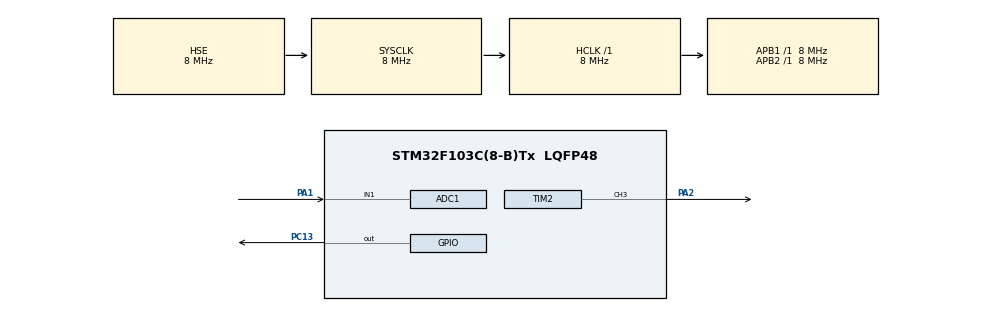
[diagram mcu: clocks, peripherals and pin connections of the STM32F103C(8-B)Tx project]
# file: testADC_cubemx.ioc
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ADC1.Channel-0\#ChannelRegularConversion=ADC_CHANNEL_1
ADC1.ContinuousConvMode=DISABLE
ADC1.ExternalTrigConv=ADC_EXTERNALTRIGCONV_T4_CC4
ADC1.NbrOfConversionFlag=1
ADC1.Rank-0\#ChannelRegularConversion=1
ADC1.SamplingTime-0\#ChannelRegularConversion=ADC_SAMPLETIME_1CYCLE_5
ADC1.master=1
Dma.ADC1.0.Direction=DMA_PERIPH_TO_MEMORY
Dma.ADC1.0.Instance=DMA1_Channel1
Dma.ADC1.0.MemDataAlignment=DMA_MDATAALIGN_HALFWORD
Dma.ADC1.0.MemInc=DMA_MINC_ENABLE
Dma.ADC1.0.Mode=DMA_CIRCULAR
Dma.ADC1.0.PeriphDataAlignment=DMA_PDATAALIGN_HALFWORD
Dma.ADC1.0.PeriphInc=DMA_PINC_DISABLE
Dma.ADC1.0.Priority=DMA_PRIORITY_HIGH
Dma.Request0=ADC1
Mcu.Family=STM32F1
Mcu.Name=STM32F103C(8-B)Tx
Mcu.Package=LQFP48
NVIC.DMA1_Channel1_IRQn=true\:0\:0\:false\:false\:true\:false\:true\:true
NVIC.PriorityGroup=NVIC_PRIORITYGROUP_4
NVIC.TIM4_IRQn=true\:0\:0\:false\:false\:true\:true\:true\:true
PA1.Signal=ADCx_IN1
PA13.Mode=Serial_Wire
PA13.Signal=SYS_JTMS-SWDIO
PA14.Mode=Serial_Wire
PA14.Signal=SYS_JTCK-SWCLK
PA2.Signal=S_TIM2_CH3
PC13-TAMPER-RTC.Signal=GPIO_Output
PD0-OSC_IN.Mode=HSE-External-Oscillator
PD0-OSC_IN.Signal=RCC_OSC_IN
PD1-OSC_OUT.Mode=HSE-External-Oscillator
PD1-OSC_OUT.Signal=RCC_OSC_OUT
ProjectManager.HeapSize=0x200
ProjectManager.StackSize=0x400
ProjectManager.TargetToolchain=MDK-ARM V5.32
RCC.ADCPresc=RCC_ADCPCLK2_DIV6
RCC.AHBFreq_Value=8000000
RCC.APB1Freq_Value=8000000
RCC.APB1TimFreq_Value=8000000
RCC.APB2Freq_Value=8000000
RCC.APB2TimFreq_Value=8000000
RCC.HCLKFreq_Value=8000000
RCC.SYSCLKFreq_VALUE=8000000
RCC.SYSCLKSource=RCC_SYSCLKSOURCE_HSE
RCC.USBFreq_Value=8000000
SH.ADCx_IN1.0=ADC1_IN1,IN1
SH.S_TIM2_CH3.0=TIM2_CH3,PWM Generation3 CH3
TIM2.Channel-PWM\ Generation3\ CH3=TIM_CHANNEL_3
TIM2.Period=4090
TIM2.Prescaler=8
TIM4.Channel-Output\ Compare4\ No\ Output=TIM_CHANNEL_4
TIM4.OCMode_4=TIM_OCMODE_TOGGLE
TIM4.Period=100
TIM4.Prescaler=3
TIM4.TIM_MasterOutputTrigger=TIM_TRGO_UPDATE
VP_TIM2_VS_ClockSourceINT.Mode=Internal
VP_TIM4_VS_ClockSourceINT.Mode=Internal
VP_TIM4_VS_no_output4.Mode=Output Compare4 No Output
board=custom

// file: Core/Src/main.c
/* USER CODE BEGIN Header */
/**
  ******************************************************************************
  * @file           : main.c
  * @brief          : Main program body
  ******************************************************************************
  * @attention
  *
  * Copyright (c) 2023 STMicroelectronics.
  * All rights reserved.
  *
  * This software is licensed under terms that can be found in the LICENSE file
  * in the root directory of this software component.
  * If no LICENSE file comes with this software, it is provided AS-IS.
  *
  ******************************************************************************
  */

/* USER CODE END Header */
#include "main.h"

//! Таймер для ШИМ
TIM_HandleTypeDef htim2;
//! Таймер для запуска АЦП
TIM_HandleTypeDef htim4;

/* USER CODE BEGIN PV */
//! массив сырых данных с АЦП
uint16_t 	adcData[ADC_SAMPLES];
//! среднее значение сырых данных
uint32_t 	adcAVG;
//! напряжение в мВ
uint32_t	adcVoltage;

//! флаг 25мс
uint8_t 	flg25ms;
//! сумма напряжений в мв за 1 сек
uint32_t 	adcSum1sec;
//! счетчик кол-ва 25мс
uint8_t 	cnt25ms;

/* USER CODE END PV */

void SystemClock_Config(void);
static void MX_GPIO_Init(void);
static void MX_DMA_Init(void);
static void MX_ADC1_Init(void);
static void MX_TIM2_Init(void);
static void MX_TIM4_Init(void);

/* USER CODE BEGIN 0 */

#include <stdio.h>

#define ITM_Port8(n)    (*((volatile unsigned char *)(0xE0000000+4*n)))
#define ITM_Port16(n)   (*((volatile unsigned short*)(0xE0000000+4*n)))
#define ITM_Port32(n)   (*((volatile unsigned long *)(0xE0000000+4*n)))
#define DEMCR           (*((volatile unsigned long *)(0xE000EDFC)))
#define TRCENA          0x01000000

struct __FILE { int handle; /* Add whatever you need here */ };

FILE __stdout;
FILE __stdin;

int fputc(int ch, FILE *f)
{
		if (DEMCR & TRCENA)
		{

			while (ITM_Port32(0) == 0);
			ITM_Port8(0) = ch;
		}
		return(ch);
}
/*
int _write(int32_t file, uint8_t *ptr, int32_t len)
{
    for (int i = 0; i < len; i++)
    {
        ITM_SendChar(*ptr++);
    }
    return len;
}
*/
/* USER CODE END 0 */

int main(void)
{

  /* MCU Configuration--------------------------------------------------------*/

  /* Reset of all peripherals, Initializes the Flash interface and the Systick. */
  HAL_Init();

  /* Configure the system clock */
  SystemClock_Config();

  /* Initialize all configured peripherals */
  MX_GPIO_Init();
  MX_DMA_Init();
  MX_ADC1_Init();
  MX_TIM2_Init();
  MX_TIM4_Init();
  /* USER CODE BEGIN 2 */

#ifdef ADC_LL
	//LL_ADC_REG_StartConversionSWStart(ADC1);
	LL_DMA_SetDataLength(DMA1, LL_DMA_CHANNEL_1, ADC_SAMPLES);

	LL_DMA_ConfigTransfer(DMA1,
                        LL_DMA_CHANNEL_1,
                        LL_DMA_DIRECTION_PERIPH_TO_MEMORY |
                        LL_DMA_MODE_CIRCULAR              |
                        LL_DMA_PERIPH_NOINCREMENT         |
                        LL_DMA_MEMORY_INCREMENT           |
                        LL_DMA_PDATAALIGN_HALFWORD        |
                        LL_DMA_MDATAALIGN_HALFWORD        |
                        LL_DMA_PRIORITY_HIGH               );

  LL_DMA_ConfigAddresses(DMA1,
                         LL_DMA_CHANNEL_1,
                         LL_ADC_DMA_GetRegAddr(ADC1, LL_ADC_DMA_REG_REGULAR_DATA),
                         (uint32_t)&adcData,
                         LL_DMA_DIRECTION_PERIPH_TO_MEMORY);

	LL_DMA_EnableChannel(DMA1, LL_DMA_CHANNEL_1);

	LL_DMA_EnableIT_TE(DMA1, LL_DMA_CHANNEL_1);
	LL_DMA_EnableIT_TC(DMA1, LL_DMA_CHANNEL_1);
	LL_ADC_Enable(ADC1);
	LL_ADC_StartCalibration(ADC1);
	while(LL_ADC_IsCalibrationOnGoing(ADC1));

	LL_ADC_REG_SetDMATransfer(ADC1,LL_ADC_REG_DMA_TRANSFER_UNLIMITED);
	LL_ADC_REG_StartConversionExtTrig(ADC1,LL_ADC_REG_TRIG_EXT_RISING);
#else
	HAL_ADCEx_Calibration_Start(&hadc1);
	HAL_ADC_Start_DMA(&hadc1, (uint32_t*)adcData, ADC_SAMPLES);
#endif

	HAL_TIM_PWM_Start(&htim2, TIM_CHANNEL_3);

	HAL_TIM_OC_Start(&htim4, TIM_CHANNEL_4);//HAL_TIM_Base_Start_IT(&htim4);//

  /* USER CODE END 2 */

  /* Infinite loop */
  /* USER CODE BEGIN WHILE */
//LL_ADC_REG_StartConversionSWStart(ADC1);
  while (1)
  {
		if (flg25ms == 1)
		{
			uint32_t adcSum=0;
			for (uint8_t i = 0; i < ADC_SAMPLES; i++)
				adcSum += adcData[i];

			adcAVG = adcSum / ADC_SAMPLES ;

	    __HAL_TIM_SET_COMPARE(&htim2, TIM_CHANNEL_3, (uint16_t)adcAVG);

			flg25ms = 0;
			adcVoltage = adcAVG * 3300 / 4096;
			adcSum1sec += adcVoltage;
			TOG_LED;
			if (++cnt25ms >= CONST_1SEC)
			{
				uint16_t adcAvg1sec = (uint16_t)(adcSum1sec/CONST_1SEC);
				printf("%u mV\r\n", adcAvg1sec);
				cnt25ms = 0;
				adcSum1sec = 0;
			}
		}
    /* USER CODE END WHILE */

  }
}

void SystemClock_Config(void)
{
  RCC_OscInitTypeDef RCC_OscInitStruct = {0};
  RCC_ClkInitTypeDef RCC_ClkInitStruct = {0};
  RCC_PeriphCLKInitTypeDef PeriphClkInit = {0};

  /** Initializes the RCC Oscillators according to the specified parameters
  * in the RCC_OscInitTypeDef structure.
  */
  RCC_OscInitStruct.OscillatorType = RCC_OSCILLATORTYPE_HSE;
  RCC_OscInitStruct.HSEState = RCC_HSE_ON;
  RCC_OscInitStruct.PLL.PLLState = RCC_PLL_NONE;
  if (HAL_RCC_OscConfig(&RCC_OscInitStruct) != HAL_OK)
  {
    Error_Handler();
  }

  /** Initializes the CPU, AHB and APB buses clocks
  */
  RCC_ClkInitStruct.ClockType = RCC_CLOCKTYPE_HCLK|RCC_CLOCKTYPE_SYSCLK
                              |RCC_CLOCKTYPE_PCLK1|RCC_CLOCKTYPE_PCLK2;
  RCC_ClkInitStruct.SYSCLKSource = RCC_SYSCLKSOURCE_HSE;
  RCC_ClkInitStruct.AHBCLKDivider = RCC_SYSCLK_DIV1;
  RCC_ClkInitStruct.APB1CLKDivider = RCC_HCLK_DIV1;
  RCC_ClkInitStruct.APB2CLKDivider = RCC_HCLK_DIV1;

  if (HAL_RCC_ClockConfig(&RCC_ClkInitStruct, FLASH_LATENCY_0) != HAL_OK)
  {
    Error_Handler();
  }
  PeriphClkInit.PeriphClockSelection = RCC_PERIPHCLK_ADC;
  PeriphClkInit.AdcClockSelection = RCC_ADCPCLK2_DIV6;
  if (HAL_RCCEx_PeriphCLKConfig(&PeriphClkInit) != HAL_OK)
  {
    Error_Handler();
  }
}

static void MX_ADC1_Init(void)
{

  LL_ADC_InitTypeDef ADC_InitStruct = {0};
  LL_ADC_CommonInitTypeDef ADC_CommonInitStruct = {0};
  LL_ADC_REG_InitTypeDef ADC_REG_InitStruct = {0};

  LL_GPIO_InitTypeDef GPIO_InitStruct = {0};

  /* Peripheral clock enable */
  LL_APB2_GRP1_EnableClock(LL_APB2_GRP1_PERIPH_ADC1);

  LL_APB2_GRP1_EnableClock(LL_APB2_GRP1_PERIPH_GPIOA);
  /**ADC1 GPIO Configuration
  PA1   ------> ADC1_IN1
  */
  GPIO_InitStruct.Pin = LL_GPIO_PIN_1;
  GPIO_InitStruct.Mode = LL_GPIO_MODE_ANALOG;
  LL_GPIO_Init(GPIOA, &GPIO_InitStruct);

  /* ADC1 DMA Init */

  /* ADC1 Init */
  LL_DMA_SetDataTransferDirection(DMA1, LL_DMA_CHANNEL_1, LL_DMA_DIRECTION_PERIPH_TO_MEMORY);

  LL_DMA_SetChannelPriorityLevel(DMA1, LL_DMA_CHANNEL_1, LL_DMA_PRIORITY_HIGH);

  LL_DMA_SetMode(DMA1, LL_DMA_CHANNEL_1, LL_DMA_MODE_CIRCULAR);

  LL_DMA_SetPeriphIncMode(DMA1, LL_DMA_CHANNEL_1, LL_DMA_PERIPH_NOINCREMENT);

  LL_DMA_SetMemoryIncMode(DMA1, LL_DMA_CHANNEL_1, LL_DMA_MEMORY_INCREMENT);

  LL_DMA_SetPeriphSize(DMA1, LL_DMA_CHANNEL_1, LL_DMA_PDATAALIGN_HALFWORD);

  LL_DMA_SetMemorySize(DMA1, LL_DMA_CHANNEL_1, LL_DMA_MDATAALIGN_HALFWORD);

  /** Common config
  */
  ADC_InitStruct.DataAlignment = LL_ADC_DATA_ALIGN_RIGHT;
  ADC_InitStruct.SequencersScanMode = LL_ADC_SEQ_SCAN_DISABLE;
  LL_ADC_Init(ADC1, &ADC_InitStruct);
  ADC_CommonInitStruct.Multimode = LL_ADC_MULTI_INDEPENDENT;
  LL_ADC_CommonInit(__LL_ADC_COMMON_INSTANCE(ADC1), &ADC_CommonInitStruct);
  ADC_REG_InitStruct.TriggerSource = LL_ADC_REG_TRIG_EXT_TIM4_CH4;
  ADC_REG_InitStruct.SequencerLength = LL_ADC_REG_SEQ_SCAN_DISABLE;
  ADC_REG_InitStruct.SequencerDiscont = LL_ADC_REG_SEQ_DISCONT_DISABLE;
  ADC_REG_InitStruct.ContinuousMode = LL_ADC_REG_CONV_SINGLE;
  ADC_REG_InitStruct.DMATransfer = LL_ADC_REG_DMA_TRANSFER_UNLIMITED;
  LL_ADC_REG_Init(ADC1, &ADC_REG_InitStruct);

  /** Configure Regular Channel
  */
  LL_ADC_REG_SetSequencerRanks(ADC1, LL_ADC_REG_RANK_1, LL_ADC_CHANNEL_1);
  LL_ADC_SetChannelSamplingTime(ADC1, LL_ADC_CHANNEL_1, LL_ADC_SAMPLINGTIME_1CYCLE_5);

}

static void MX_TIM2_Init(void)
{

  TIM_ClockConfigTypeDef sClockSourceConfig = {0};
  TIM_MasterConfigTypeDef sMasterConfig = {0};
  TIM_OC_InitTypeDef sConfigOC = {0};

  htim2.Instance = TIM2;
  htim2.Init.Prescaler = 8;
  htim2.Init.CounterMode = TIM_COUNTERMODE_UP;
  htim2.Init.Period = 4090;
  htim2.Init.ClockDivision = TIM_CLOCKDIVISION_DIV1;
  htim2.Init.AutoReloadPreload = TIM_AUTORELOAD_PRELOAD_DISABLE;
  if (HAL_TIM_Base_Init(&htim2) != HAL_OK)
  {
    Error_Handler();
  }
  sClockSourceConfig.ClockSource = TIM_CLOCKSOURCE_INTERNAL;
  if (HAL_TIM_ConfigClockSource(&htim2, &sClockSourceConfig) != HAL_OK)
  {
    Error_Handler();
  }
  if (HAL_TIM_PWM_Init(&htim2) != HAL_OK)
  {
    Error_Handler();
  }
  sMasterConfig.MasterOutputTrigger = TIM_TRGO_RESET;
  sMasterConfig.MasterSlaveMode = TIM_MASTERSLAVEMODE_DISABLE;
  if (HAL_TIMEx_MasterConfigSynchronization(&htim2, &sMasterConfig) != HAL_OK)
  {
    Error_Handler();
  }
  sConfigOC.OCMode = TIM_OCMODE_PWM1;
  sConfigOC.Pulse = 0;
  sConfigOC.OCPolarity = TIM_OCPOLARITY_HIGH;
  sConfigOC.OCFastMode = TIM_OCFAST_DISABLE;
  if (HAL_TIM_PWM_ConfigChannel(&htim2, &sConfigOC, TIM_CHANNEL_3) != HAL_OK)
  {
    Error_Handler();
  }
  HAL_TIM_MspPostInit(&htim2);

}

static void MX_TIM4_Init(void)
{

  TIM_ClockConfigTypeDef sClockSourceConfig = {0};
  TIM_MasterConfigTypeDef sMasterConfig = {0};
  TIM_OC_InitTypeDef sConfigOC = {0};

  htim4.Instance = TIM4;
  htim4.Init.Prescaler = 3;
  htim4.Init.CounterMode = TIM_COUNTERMODE_UP;
  htim4.Init.Period = 100;
  htim4.Init.ClockDivision = TIM_CLOCKDIVISION_DIV1;
  htim4.Init.AutoReloadPreload = TIM_AUTORELOAD_PRELOAD_DISABLE;
  if (HAL_TIM_Base_Init(&htim4) != HAL_OK)
  {
    Error_Handler();
  }
  sClockSourceConfig.ClockSource = TIM_CLOCKSOURCE_INTERNAL;
  if (HAL_TIM_ConfigClockSource(&htim4, &sClockSourceConfig) != HAL_OK)
  {
    Error_Handler();
  }
  if (HAL_TIM_OC_Init(&htim4) != HAL_OK)
  {
    Error_Handler();
  }
  sMasterConfig.MasterOutputTrigger = TIM_TRGO_UPDATE;
  sMasterConfig.MasterSlaveMode = TIM_MASTERSLAVEMODE_DISABLE;
  if (HAL_TIMEx_MasterConfigSynchronization(&htim4, &sMasterConfig) != HAL_OK)
  {
    Error_Handler();
  }
  sConfigOC.OCMode = TIM_OCMODE_TOGGLE;
  sConfigOC.Pulse = 0;
  sConfigOC.OCPolarity = TIM_OCPOLARITY_HIGH;
  sConfigOC.OCFastMode = TIM_OCFAST_DISABLE;
  if (HAL_TIM_OC_ConfigChannel(&htim4, &sConfigOC, TIM_CHANNEL_4) != HAL_OK)
  {
    Error_Handler();
  }

}

static void MX_DMA_Init(void)
{

  /* Init with LL driver */
  /* DMA controller clock enable */
  LL_AHB1_GRP1_EnableClock(LL_AHB1_GRP1_PERIPH_DMA1);

  /* DMA interrupt init */
  /* DMA1_Channel1_IRQn interrupt configuration */
  NVIC_SetPriority(DMA1_Channel1_IRQn, NVIC_EncodePriority(NVIC_GetPriorityGrouping(),0, 0));
  NVIC_EnableIRQ(DMA1_Channel1_IRQn);

}

static void MX_GPIO_Init(void)
{
  GPIO_InitTypeDef GPIO_InitStruct = {0};

  /* GPIO Ports Clock Enable */
  __HAL_RCC_GPIOC_CLK_ENABLE();
  __HAL_RCC_GPIOD_CLK_ENABLE();
  __HAL_RCC_GPIOA_CLK_ENABLE();

  /*Configure GPIO pin Output Level */
  HAL_GPIO_WritePin(GPIOC, GPIO_PIN_13, GPIO_PIN_RESET);

  /*Configure GPIO pin : PC13 */
  GPIO_InitStruct.Pin = GPIO_PIN_13;
  GPIO_InitStruct.Mode = GPIO_MODE_OUTPUT_PP;
  GPIO_InitStruct.Pull = GPIO_NOPULL;
  GPIO_InitStruct.Speed = GPIO_SPEED_FREQ_LOW;
  HAL_GPIO_Init(GPIOC, &GPIO_InitStruct);

}

/* USER CODE BEGIN 4 */
/*
void HAL_TIM_PeriodElapsedCallback(TIM_HandleTypeDef *htim)
{
  if(htim->Instance == TIM4)
  {
		//HAL_GPIO_TogglePin(GPIOC, GPIO_PIN_13);
    TOG_LED;
  }
}
*/

#ifdef ADC_LL
/**
@brief	Функция выставления флага завершения сбора сырых данных с АЦП при помощи ПДП	используя библиотеку LL
@return
*/
void ADC_DMA_TransferComplete_Callback()
{
  flg25ms = 1;
}
#else
/**
@brief	Функция выставления флага завершения сбора сырых данных с АЦП при помощи ПДП	используя библиотеку HAL
@param *hadc	указатель на АЦП
@return
*/void HAL_ADC_ConvCpltCallback(ADC_HandleTypeDef* hadc)
{
  if(hadc->Instance == ADC1)
  {
		flg25ms = 1;
  }
}
#endif

/* USER CODE END 4 */

void Error_Handler(void)
{
  __disable_irq();
  while (1)
  {
  }
}
